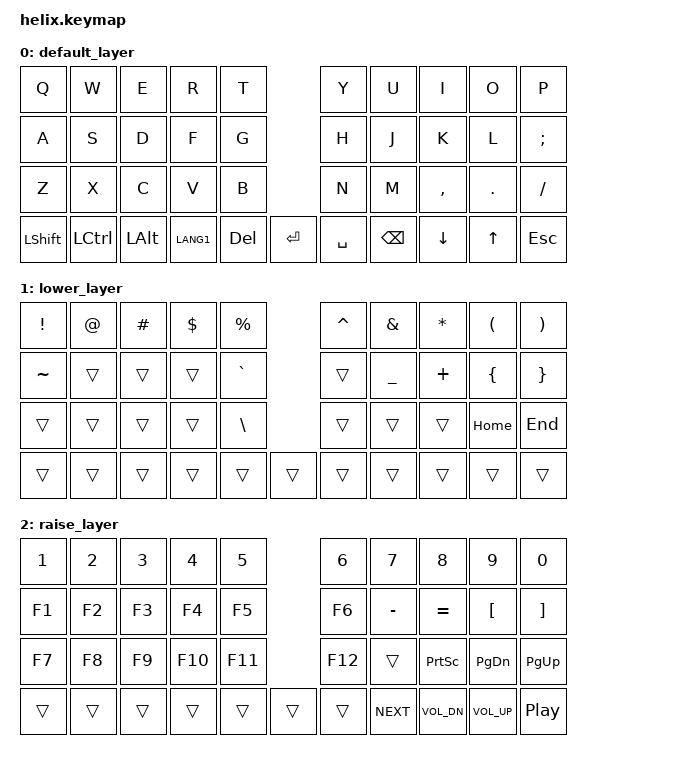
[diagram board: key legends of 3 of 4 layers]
/*
 * Copyright (c) 2020 The ZMK Contributors
 *
 * SPDX-License-Identifier: MIT
 */

 #include <behaviors.dtsi>
 #include <dt-bindings/zmk/keys.h>
 #include <dt-bindings/zmk/bt.h>
 #include <dt-bindings/zmk/rgb.h>
 #include <dt-bindings/zmk/ext_power.h>
 #include <dt-bindings/zmk/outputs.h>

 #define DEFAULT 0
 #define LOWER  1
 #define RAISE  2
 #define ADJUST 3

/* NOTE: At the time of the creation of this keymap, there are no specified codes for 'eisuu' and 'kana' input in ZMK.
However, 'LANG1' and 'LANG2' are fully-functioning candidates for 'kana' and 'eisuu' input respectively.
As such, those are in use within the default layer at this time.*/

/ {
       keymap {
              compatible = "zmk,keymap";

              default_layer {
 // ---------------------------------------------------------------------------------------------------------------------------------
 // |   Q    |   W    |   E    |   R    |   T    |                                      |   Y    |   U    |   I    |   O    |   P    |
 // |   A    |   S    |   D    |   F    |   G    |                                      |   H    |   J    |   K    |   L    |   ;    |
 // |   Z    |   X    |   C    |   V    |   B    |                                      |   N    |   M    |   ,    |   .    |   /    |
 // |  SHIFT |  CTRL  |  ALT   |  KANA  |  DEL   |  RET   |                             |  SPACE |  BSPC  |  DOWN  |  UP    |  ESC   |
                     bindings = <
       &kp Q      &kp W      &kp E     &kp R      &kp T                             &kp Y      &kp U     &kp I      &kp O       &kp P
       &kp A      &kp S      &kp D     &kp F      &kp G                             &kp H      &kp J     &kp K      &kp L       &kp SEMI
       &kp Z      &kp X      &kp C     &kp V      &kp B                             &kp N      &kp M     &kp COMMA  &kp PERIOD  &kp SLASH
       &kp LSHFT  &kp LCTRL  &kp LALT  &kp LANG1  &kp DEL  &kp RET                  &kp SPACE  &kp BSPC  &kp DOWN   &kp UP      &kp ESC
                     >;
              };
              lower_layer {
 // ---------------------------------------------------------------------------------------------------------------------------------
 // |  !   |  @   |  #   |  $   |  %   |                           |  ^   |  &   |  *   |  (   |  )   |      |
 // |  ~   |      |      |      |   `  |                           |      |  _   |  +   |  {   |  }   | PIPE |
 // |      |      |      |      |   \  |                           |  )   |      |      |      | HOME | END  |
 // |      |      |      |      |      |  (   |                    |      |      |      |      |      |      |
                     bindings = <
       &kp EXCL   &kp AT  &kp HASH  &kp DLLR  &kp PRCNT                    &kp CARET  &kp AMPS   &kp ASTRK  &kp LPAR  &kp RPAR
       &kp TILDE  &trans  &trans    &trans    &kp GRAVE                    &trans     &kp UNDER  &kp PLUS   &kp LBRC  &kp RBRC
       &trans     &trans  &trans    &trans    &kp BSLH                     &trans     &trans     &trans     &kp HOME  &kp END 
       &trans     &trans  &trans    &trans    &trans     &trans            &trans     &trans     &trans     &trans    &trans
                     >;
              };
              raise_layer {
 // ---------------------------------------------------------------------------------------------------------------------------------
 // |   1   |   2   |   3   |   4   |   5   |                                    |   6   |   7   |   8   |   9   |   0   |
 // |  F1   |  F2   |  F3   |  F4   |  F5   |                                    |  F6   |   -   |   =   |   [   |   ]   |
 // |  F7   |  F8   |  F9   |  F10  |  F11  |                                    |  F12  |       | PSCRN | PG_DN | PG_UP |
 // |       |       |       |       |       |       |                            |       | NEXT  | VOL-  | VOL+  | PLAY  |
                     bindings = <
       &kp N1  &kp N2  &kp N3  &kp N4   &kp N5                       &kp N6   &kp N7      &kp N8        &kp N9        &kp N0
       &kp F1  &kp F2  &kp F3  &kp F4   &kp F5                       &kp F6   &kp MINUS   &kp EQUAL     &kp LBKT      &kp RBKT
       &kp F7  &kp F8  &kp F9  &kp F10  &kp F11                      &kp F12  &trans      &kp PSCRN     &kp PG_DN     &kp PG_UP
       &trans  &trans  &trans  &trans   &trans  &trans               &trans   &kp C_NEXT  &kp C_VOL_DN  &kp C_VOL_UP  &kp C_PP
                     >;
              };
              adjust_layer {
 // ---------------------------------------------------------------------------------------------------------------------------------
 // |  BT CLR  | BT SEL0  | BT SEL1  | BT SEL2  | BGT SEL3 | BT SEL4  |                                          | RGB EFF+ | RGB HUE+ | RGB SAT+ | RGB SPD+ | RGB BRI+ | RGB TOG  |
 // |  BT NXT  | OUT TOG  | OUT USB  | OUT BLE  |          |          |                                          | RGB EFF- | RGB HUE- | RGB SAT- | RGB SPD- | RGB BRI- |          |
 // |  BT PRV  |          |          |          |          |          |    {     |                    |    }     |          |          |          |          |          |          |
 // |          |          |          |          |          |          |          |                    |          |          |          |          |          |          |          |
                     bindings = <
       &bt BT_CLR &bt BT_SEL 0 &bt BT_SEL 1 &bt BT_SEL 2 &bt BT_SEL 3 &bt BT_SEL 4                          &rgb_ug RGB_EFF &rgb_ug RGB_HUI &rgb_ug RGB_SAI &rgb_ug RGB_SPI &rgb_ug RGB_BRI &rgb_ug RGB_TOG
       &bt BT_NXT &out OUT_TOG &out OUT_USB &out OUT_BLE &trans       &trans                                &rgb_ug RGB_EFR &rgb_ug RGB_HUD &rgb_ug RGB_SAD &rgb_ug RGB_SPD &rgb_ug RGB_BRD &trans
       &bt BT_PRV &trans       &trans       &trans       &trans       &trans       &kp LBRC        &kp RBRC &trans          &trans          &trans          &trans          &trans          &trans
       &trans     &trans       &trans       &trans       &trans       &trans       &trans          &trans   &trans          &trans          &trans          &trans          &trans          &trans
                     >;
              };
       };
};
